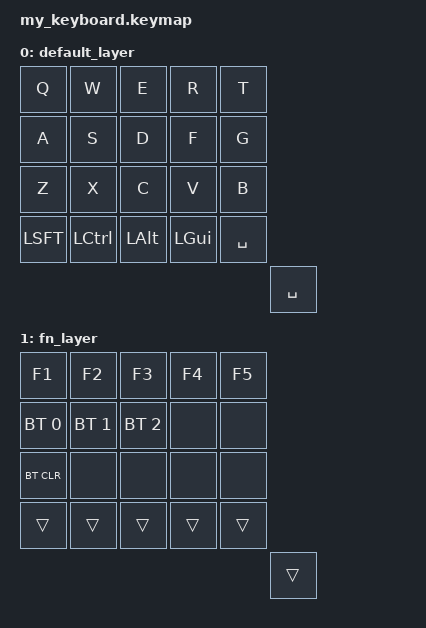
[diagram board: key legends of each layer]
#include <behaviors.dtsi>
#include <dt-bindings/zmk/keys.h>
#include <dt-bindings/zmk/bt.h>

/ {
    keymap {
        compatible = "zmk,keymap";

        default_layer {
            bindings = 
                &kp Q  &kp W  &kp E  &kp R  &kp T
                &kp A  &kp S  &kp D  &kp F  &kp G
                &kp Z  &kp X  &kp C  &kp V  &kp B
                &kp LSFT &kp LCTL &kp LALT &kp LGUI &kp SPC
                                                     &kp SPACE
            >;
        };

        fn_layer {
            bindings = 
                &kp F1       &kp F2       &kp F3       &kp F4 &kp F5
                &bt BT_SEL 0 &bt BT_SEL 1 &bt BT_SEL 2 &none &none
                &bt BT_CLR   &none        &none        &none  &none
                &trans       &trans       &trans       &trans &trans
                                                              &trans
            >;
        };
    };
};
